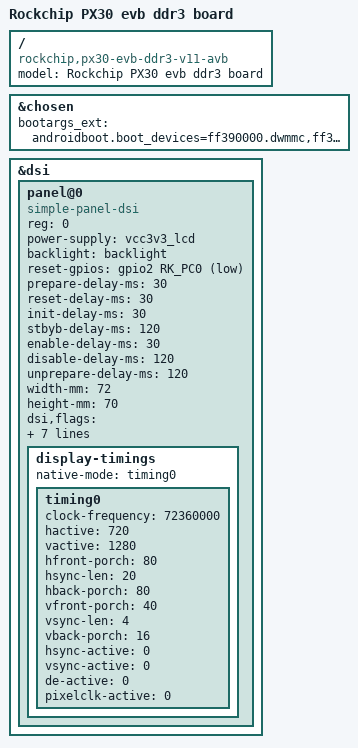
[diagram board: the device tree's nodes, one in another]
// SPDX-License-Identifier: (GPL-2.0+ OR MIT)
/*
 * Copyright (c) 2017-2020 Rockchip Electronics Co., Ltd
 */

/dts-v1/;
#include "px30-evb-ddr3-v10.dtsi"

/ {
	model = "Rockchip PX30 evb ddr3 board";
	compatible = "rockchip,px30-evb-ddr3-v11-avb", "rockchip,px30";
};

&chosen {
	bootargs_ext = "androidboot.boot_devices=ff390000.dwmmc,ff3b0000.nandc";
};

&dsi {
	status = "okay";
	// rockchip,lane-rate = <213>;

	panel@0 {
		compatible = "simple-panel-dsi";
		reg = <0>;
		power-supply = <&vcc3v3_lcd>;
		backlight = <&backlight>;
		
		reset-gpios = <&gpio2 RK_PC0 GPIO_ACTIVE_LOW>; /* GPIO3_A5 LCD_RST */
		// enable-gpios = <&gpio2 RK_PB4 GPIO_ACTIVE_HIGH>;
		// reset-delay-ms = <20>;
		// init-delay-ms = <20>;
		// enable-delay-ms = <40>;
		// prepare-delay-ms = <20>;
		// disable-delay-ms = <20>;
		// unprepare-delay-ms = <20>;

		prepare-delay-ms = <30>;
		reset-delay-ms = <30>;
		init-delay-ms = <30>;
		stbyb-delay-ms = <120>;
		enable-delay-ms = <30>;
		disable-delay-ms = <120>;
		unprepare-delay-ms = <120>;

		width-mm = <72>;
		height-mm = <70>;

		// dsi,flags = <(MIPI_DSI_MODE_VIDEO | MIPI_DSI_MODE_VIDEO_BURST |
		// 	      MIPI_DSI_MODE_LPM | MIPI_DSI_MODE_EOT_PACKET)>; 
		// dsi,flags = <(MIPI_DSI_MODE_VIDEO | MIPI_DSI_MODE_VIDEO_BURST | MIPI_DSI_MODE_LPM)>;
		dsi,flags = <(MIPI_DSI_MODE_VIDEO | MIPI_DSI_MODE_VIDEO_BURST | MIPI_DSI_MODE_LPM| MIPI_DSI_MODE_EOT_PACKET)>;

		dsi,format = <MIPI_DSI_FMT_RGB888>;
		dsi,lanes = <4>;
		status = "okay";

		panel-init-sequence = [
			39 00 04 FF 98 81 03
			15 00 02 01 00
			15 00 02 02 00
			15 00 02 03 73
			15 00 02 04 00
			15 00 02 05 00
			15 00 02 06 0C
			15 00 02 07 00
			15 00 02 08 00
			15 00 02 09 19
			15 00 02 0a 01
			15 00 02 0b 01
			15 00 02 0c 0B
			15 00 02 0d 01
			15 00 02 0e 01
			15 00 02 0f 26
			15 00 02 10 26
			15 00 02 11 00
			15 00 02 12 00
			15 00 02 13 02
			15 00 02 14 00
			15 00 02 15 00
			15 00 02 16 00
			15 00 02 17 00
			15 00 02 18 00
			15 00 02 19 00
			15 00 02 1a 00
			15 00 02 1b 00
			15 00 02 1c 00
			15 00 02 1d 00
			15 00 02 1e 44
			15 00 02 1f C0
			15 00 02 20 0A
			15 00 02 21 03
			15 00 02 22 0A
			15 00 02 23 00
			15 00 02 24 8C
			15 00 02 25 8C
			15 00 02 26 00
			15 00 02 27 00
			15 00 02 28 3B
			15 00 02 29 03
			15 00 02 2a 00
			15 00 02 2b 00
			15 00 02 2c 00
			15 00 02 2d 00
			15 00 02 2e 00
			15 00 02 2f 00
			15 00 02 30 00
			15 00 02 31 00
			15 00 02 32 00
			15 00 02 33 00
			15 00 02 34 00
			15 00 02 35 00
			15 00 02 36 00
			15 00 02 37 00
			15 00 02 38 00
			15 00 02 39 00
			15 00 02 3a 00
			15 00 02 3b 00
			15 00 02 3c 00
			15 00 02 3d 00
			15 00 02 3e 00
			15 00 02 3f 00
			15 00 02 40 00
			15 00 02 41 00
			15 00 02 42 00
			15 00 02 43 00
			15 00 02 44 00
			15 00 02 50 01
			15 00 02 51 23
			15 00 02 52 45
			15 00 02 53 67
			15 00 02 54 89
			15 00 02 55 ab
			15 00 02 56 01
			15 00 02 57 23
			15 00 02 58 45
			15 00 02 59 67
			15 00 02 5a 89
			15 00 02 5b ab
			15 00 02 5c cd
			15 00 02 5d ef
			15 00 02 5e 11
			15 00 02 5f 02
			15 00 02 60 00
			15 00 02 61 0C
			15 00 02 62 0D
			15 00 02 63 0E
			15 00 02 64 0F
			15 00 02 65 02
			15 00 02 66 02
			15 00 02 67 02
			15 00 02 68 02
			15 00 02 69 02
			15 00 02 6a 02
			15 00 02 6b 02
			15 00 02 6c 02
			15 00 02 6d 02
			15 00 02 6e 05
			15 00 02 6f 05
			15 00 02 70 05
			15 00 02 71 05
			15 00 02 72 01
			15 00 02 73 06
			15 00 02 74 07
			15 00 02 75 02
			15 00 02 76 00
			15 00 02 77 0C
			15 00 02 78 0D
			15 00 02 79 0E
			15 00 02 7a 0F
			15 00 02 7b 02
			15 00 02 7c 02
			15 00 02 7d 02
			15 00 02 7e 02
			15 00 02 7f 02
			15 00 02 80 02
			15 00 02 81 02
			15 00 02 82 02
			15 00 02 83 02
			15 00 02 84 05
			15 00 02 85 05
			15 00 02 86 05
			15 00 02 87 05
			15 00 02 88 01
			15 00 02 89 06
			15 00 02 8A 07
			39 00 04 FF 98 81 04
			15 00 02 38 01
			15 00 02 39 00
			15 00 02 6C 15
			15 00 02 6E 1A
			15 00 02 6F 25
			15 00 02 3A 24
			15 00 02 8D 1F
			15 00 02 87 BA
			15 00 02 35 1f
			39 00 04 FF 98 81 01
			15 00 02 22 0A
			15 00 02 31 00
			15 00 02 40 33
			15 00 02 43 66
			15 00 02 50 6e
			15 00 02 51 6a
			15 00 02 53 7c
			15 00 02 55 7c
			15 00 02 60 19
			15 00 02 61 01
			15 00 02 62 0c
			15 00 02 63 00
			39 00 04 FF 98 81 01
			15 00 02 A0 03
			15 00 02 A1 11
			15 00 02 A2 1C
			15 00 02 A3 11
			15 00 02 A4 13
			15 00 02 A5 24
			15 00 02 A6 19
			15 00 02 A7 1B
			15 00 02 A8 6E
			15 00 02 A9 1C
			15 00 02 AA 28
			15 00 02 AB 66
			15 00 02 AC 1A
			15 00 02 AD 16
			15 00 02 AE 4B
			15 00 02 AF 1E
			15 00 02 B0 25
			15 00 02 B1 4F
			15 00 02 B2 61
			15 00 02 B3 39
			15 00 02 C0 03
			15 00 02 C1 11
			15 00 02 C2 1C
			15 00 02 C3 11
			15 00 02 C4 13
			15 00 02 C5 24
			15 00 02 C6 19
			15 00 02 C7 1B
			15 00 02 C8 6E
			15 00 02 C9 1C
			15 00 02 CA 28
			15 00 02 CB 66
			15 00 02 CC 1A
			15 00 02 CD 16
			15 00 02 CE 4B
			15 00 02 CF 1E
			15 00 02 D0 25
			15 00 02 D1 4F
			15 00 02 D2 61
			15 00 02 D3 39
			39 00 04 FF 98 81 00
			15 00 02 35 00
			05 78 01 11
			05 78 01 29
		];

		panel-exit-sequence = [
			05 00 01 28
			05 78 01 10
		];

		display-timings {
			native-mode = <&timing0>;

			timing0: timing0 {
				clock-frequency = <72360000>;   //900*1340*60 = 72360000 
				hactive = <720>;
				vactive = <1280>;
				hfront-porch = <80>;
				hsync-len = <20>;
				hback-porch = <80>;
				vfront-porch = <40>;
				vsync-len = <4>;
				vback-porch = <16>;
				hsync-active = <0>;
				vsync-active = <0>;
				de-active = <0>;
				pixelclk-active = <0>;
			};
		};
	};
};


// &dsi {
// 	status = "okay";
// 	// rockchip,lane-rate = <213>;

// 	panel@0 {
// 		compatible = "simple-panel-dsi";
// 		reg = <0>;
// 		power-supply = <&vcc3v3_lcd>;
// 		backlight = <&backlight>;
		
// 		reset-gpios = <&gpio2 RK_PC0 GPIO_ACTIVE_LOW>; /* GPIO3_A5 LCD_RST */
// 		// enable-gpios = <&gpio2 RK_PB4 GPIO_ACTIVE_HIGH>;

// 		prepare-delay-ms = <30>;
// 		reset-delay-ms = <30>;
// 		init-delay-ms = <30>;
// 		stbyb-delay-ms = <120>;
// 		enable-delay-ms = <30>;
// 		disable-delay-ms = <120>;
// 		unprepare-delay-ms = <120>;

// 		width-mm = <72>;
// 		height-mm = <70>;

// 		// dsi,flags = <(MIPI_DSI_MODE_VIDEO | MIPI_DSI_MODE_VIDEO_BURST |
// 		// 	      MIPI_DSI_MODE_LPM | MIPI_DSI_MODE_EOT_PACKET)>; 
// 		// dsi,flags = <(MIPI_DSI_MODE_VIDEO | MIPI_DSI_MODE_VIDEO_BURST | MIPI_DSI_MODE_LPM)>;
// 		dsi,flags = <(MIPI_DSI_MODE_VIDEO | MIPI_DSI_MODE_VIDEO_BURST | MIPI_DSI_MODE_LPM| MIPI_DSI_MODE_EOT_PACKET)>;

// 		dsi,format = <MIPI_DSI_FMT_RGB888>;
// 		dsi,lanes = <4>;
// 		status = "okay";

// 		panel-init-sequence = [
// 			39 00 04 FF 98 81 03
// 			15 00 02 01 00
// 			15 00 02 02 00
// 			15 00 02 03 53
// 			15 00 02 04 00
// 			15 00 02 05 00
// 			15 00 02 06 08
// 			15 00 02 07 00
// 			15 00 02 08 00
// 			15 00 02 09 00
// 			15 00 02 0a 00
// 			15 00 02 0b 00
// 			15 00 02 0c 00
// 			15 00 02 0d 00
// 			15 00 02 0e 00
// 			15 00 02 0f 26
// 			15 00 02 10 26
// 			15 00 02 11 00
// 			15 00 02 12 00
// 			15 00 02 13 00
// 			15 00 02 14 00
// 			15 00 02 C4 1E
// 			15 00 02 C5 33
// 			15 00 02 C6 27
// 			15 00 02 C7 26
// 			15 00 02 C8 AF
// 			15 00 02 C9 1B
// 			15 00 02 CA 27
// 			15 00 02 CB 8D
// 			15 00 02 CC 1A
// 			15 00 02 CD 1B
// 			15 00 02 CE 50
// 			15 00 02 CF 26
// 			15 00 02 D0 2B
// 			15 00 02 D1 54
// 			15 00 02 D2 5E
// 			15 00 02 D3 23
// 			//39 00 04 FF 98 81 04
// 			//15 00 02 2F 01			
// 			39 00 04 FF 98 81 00
// 			15 00 02 35 00
// 			05 78 01 11
// 			05 78 01 29
// 		];

// 		panel-exit-sequence = [
// 			05 00 01 28
// 			05 78 01 10
// 		];

// 		display-timings {
// 			native-mode = <&timing0>;

// 			timing0: timing0 {
// 				clock-frequency = <69000000>;//872
// 				hactive = <1024>;
// 				vactive = <600>;
				
// 				hback-porch = <54>;
// 				hfront-porch = <54>;
// 				vback-porch = <23>;
// 				vfront-porch = <12>;
// 				hsync-len = <36>;
// 				vsync-len = <10>;
				
// 				hsync-active = <0>;
// 				vsync-active = <0>;
				
// 				de-active = <0>;
// 				pixelclk-active = <0>;
// 			};
// 		};
// 	};
// };

